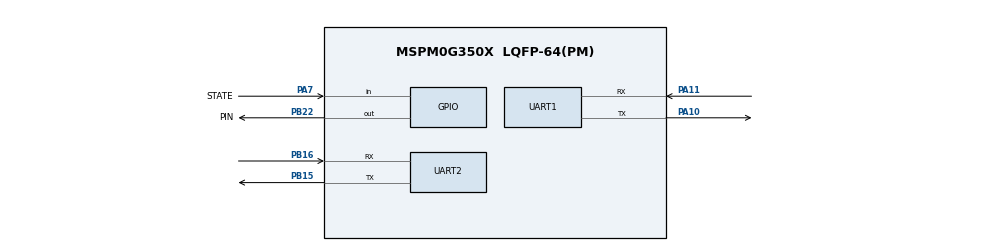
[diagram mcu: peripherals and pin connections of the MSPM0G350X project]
/**
 * @cliArgs --device "MSPM0G350X" --part "Default" --package "LQFP-64(PM)" --product "mspm0_sdk@2.02.00.05"
 * @versions {"tool":"1.21.0+3721"}
 */

/**
 * Import the modules used in this configuration.
 */
const GPIO   = scripting.addModule("/ti/driverlib/GPIO", {}, false);
const GPIO1  = GPIO.addInstance();
const GPIO2  = GPIO.addInstance();
const SYSCTL = scripting.addModule("/ti/driverlib/SYSCTL");
const UART   = scripting.addModule("/ti/driverlib/UART", {}, false);
const UART1  = UART.addInstance();
const UART2  = UART.addInstance();

/**
 * Write custom configuration values to the imported modules.
 */
const divider9       = system.clockTree["UDIV"];
divider9.divideValue = 2;

const mux4       = system.clockTree["EXHFMUX"];
mux4.inputSelect = "EXHFMUX_XTAL";

const mux8       = system.clockTree["HSCLKMUX"];
mux8.inputSelect = "HSCLKMUX_SYSPLL2X";

const mux12       = system.clockTree["SYSPLLMUX"];
mux12.inputSelect = "zSYSPLLMUX_HFCLK";

const pinFunction4        = system.clockTree["HFXT"];
pinFunction4.inputFreq    = 40;
pinFunction4.enable       = true;
pinFunction4.HFCLKMonitor = true;
pinFunction4.HFXTStartup  = 20;

GPIO1.$name                          = "LED";
GPIO1.associatedPins[0].$name        = "PIN";
GPIO1.associatedPins[0].ioStructure  = "SD";
GPIO1.associatedPins[0].assignedPort = "PORTB";
GPIO1.associatedPins[0].assignedPin  = "22";
GPIO1.associatedPins[0].pin.$assign  = "PB22";

const Board = scripting.addModule("/ti/driverlib/Board", {}, false);

GPIO2.$name                         = "HC05";
GPIO2.port                          = "PORTA";
GPIO2.associatedPins[0].assignedPin = "7";
GPIO2.associatedPins[0].direction   = "INPUT";
GPIO2.associatedPins[0].$name       = "STATE";
GPIO2.associatedPins[0].pin.$assign = "PA7";

SYSCTL.forceDefaultClkConfig = true;
SYSCTL.clockTreeEn           = true;
SYSCTL.validateClkStatus     = true;

UART1.$name                        = "UART_0";
UART1.targetBaudRate               = 115200;
UART1.peripheral.$assign           = "UART0";
UART1.peripheral.rxPin.$assign     = "PA11";
UART1.peripheral.txPin.$assign     = "PA10";
UART1.txPinConfig.$name            = "ti_driverlib_gpio_GPIOPinGeneric0";
UART1.txPinConfig.enableConfig     = true;
UART1.txPinConfig.internalResistor = "PULL_UP";
UART1.rxPinConfig.$name            = "ti_driverlib_gpio_GPIOPinGeneric1";
UART1.rxPinConfig.enableConfig     = true;
UART1.rxPinConfig.internalResistor = "PULL_UP";

UART2.uartClkDiv                       = "4";
UART2.enabledInterrupts                = ["RX"];
UART2.$name                            = "UART_2";
UART2.peripheral.$assign               = "UART2";
UART2.peripheral.rxPin.$assign         = "PB16";
UART2.peripheral.txPin.$assign         = "PB15";
UART2.txPinConfig.$name                = "ti_driverlib_gpio_GPIOPinGeneric2";
UART2.txPinConfig.direction            = scripting.forceWrite("OUTPUT");
UART2.txPinConfig.hideOutputInversion  = scripting.forceWrite(false);
UART2.txPinConfig.onlyInternalResistor = scripting.forceWrite(false);
UART2.txPinConfig.passedPeripheralType = scripting.forceWrite("Digital");
UART2.rxPinConfig.$name                = "ti_driverlib_gpio_GPIOPinGeneric3";
UART2.rxPinConfig.hideOutputInversion  = scripting.forceWrite(false);
UART2.rxPinConfig.onlyInternalResistor = scripting.forceWrite(false);
UART2.rxPinConfig.passedPeripheralType = scripting.forceWrite("Digital");

/**
 * Pinmux solution for unlocked pins/peripherals. This ensures that minor changes to the automatic solver in a future
 * version of the tool will not impact the pinmux you originally saw.  These lines can be completely deleted in order to
 * re-solve from scratch.
 */
pinFunction4.peripheral.$suggestSolution           = "SYSCTL";
pinFunction4.peripheral.hfxInPin.$suggestSolution  = "PA5";
pinFunction4.peripheral.hfxOutPin.$suggestSolution = "PA6";
Board.peripheral.$suggestSolution                  = "DEBUGSS";
Board.peripheral.swclkPin.$suggestSolution         = "PA20";
Board.peripheral.swdioPin.$suggestSolution         = "PA19";
